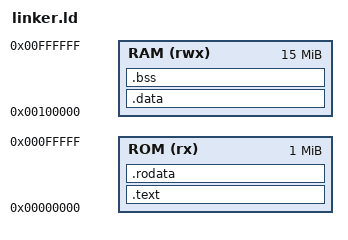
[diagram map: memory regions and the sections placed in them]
/* Illustrative memory regions only. Adapt to the verified platform. */
ENTRY(_start)
MEMORY
{
    ROM (rx)  : ORIGIN = 0x00000000, LENGTH = 1M
    RAM (rwx) : ORIGIN = 0x00100000, LENGTH = 15M
}
SECTIONS
{
    .text : { *(.text*) } > ROM
    .rodata : { *(.rodata*) } > ROM
    .data : { *(.data*) } > RAM
    .bss : { *(.bss*) } > RAM
}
